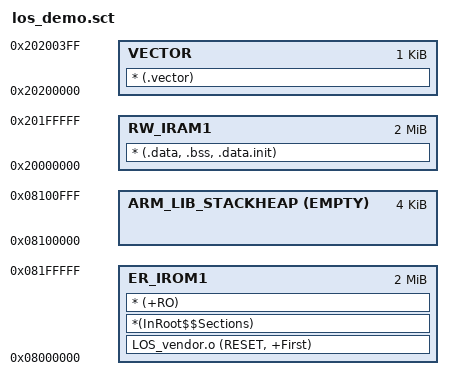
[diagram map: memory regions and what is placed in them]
; *************************************************************
; *** Scatter-Loading Description File generated by uVision ***
; *************************************************************

LR_IROM1 0x08000000 0x00200000  {    ; load region size_region
  ER_IROM1 0x08000000 0x00200000  {  ; load address = execution address
   	LOS_vendor.o (RESET, +First)
   *(InRoot$$Sections)
   * (+RO)
  }
  RW_IRAM1 0x20000000 0x00200000  {  ; RW data
      * (.data, .bss, .data.init)
  }
    VECTOR 0x20200000 0x400         ; Vector
  {
	* (.vector)
  }
  
  ARM_LIB_STACKHEAP 0x08100000 EMPTY 0x1000 
  {
	
  }	
}

